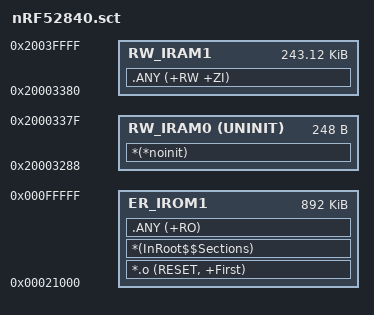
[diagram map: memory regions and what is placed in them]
#! armcc -E

#if !defined(MBED_APP_START)
  #define MBED_APP_START 0x21000
#endif

#if !defined(MBED_APP_SIZE)
  #define MBED_APP_SIZE 0xDF000
#endif

LR_IROM1 MBED_APP_START MBED_APP_SIZE  {
  ER_IROM1 MBED_APP_START MBED_APP_SIZE  {
   *.o (RESET, +First)
   *(InRoot$$Sections)
   .ANY (+RO)
  }
  RW_IRAM0 0x20003288 UNINIT 0x000000F8  { ;no init section
        *(*noinit)
  }
  RW_IRAM1 0x20003380 0x0003cc80  {
   .ANY (+RW +ZI)
  }
}
